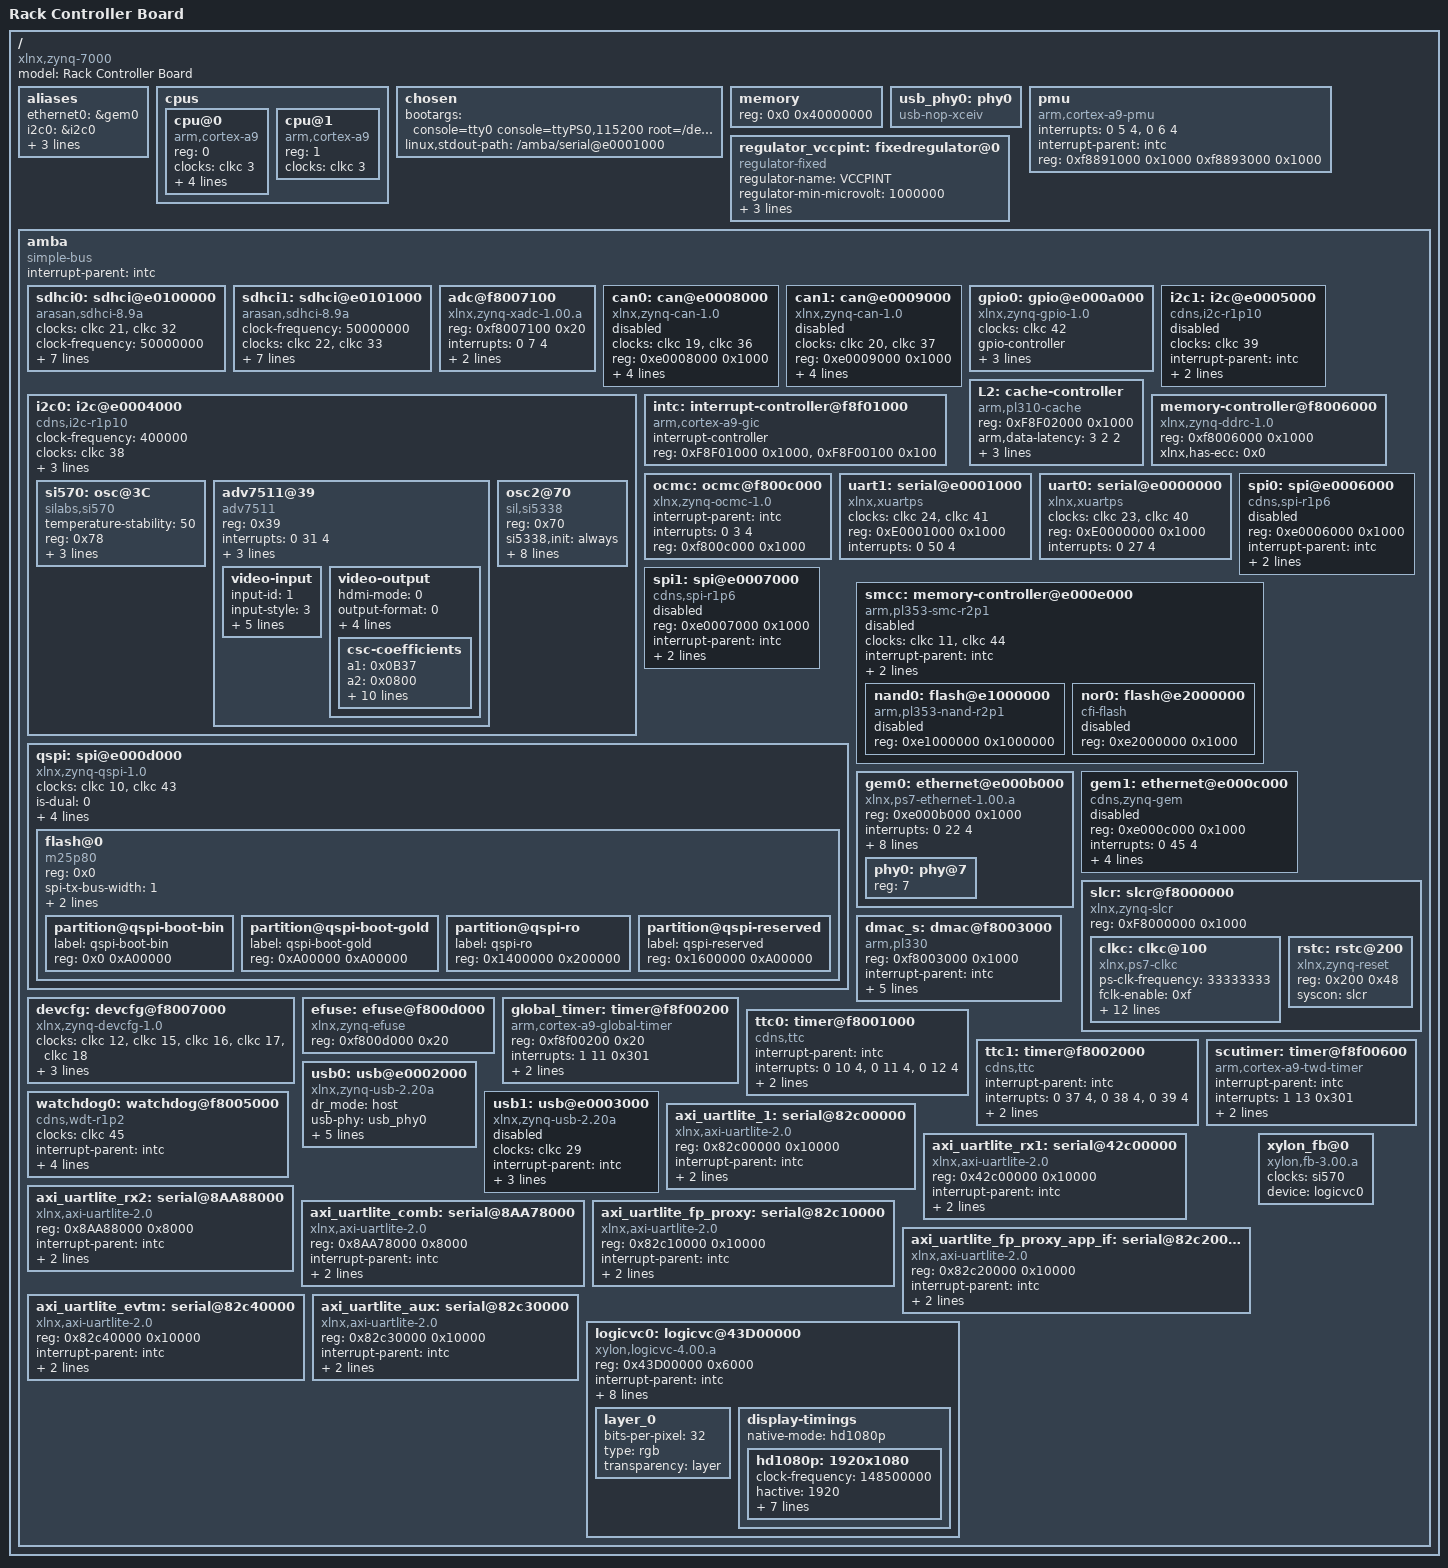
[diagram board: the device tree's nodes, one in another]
/ {
	model = "Rack Controller Board";
	compatible = "xlnx,zynq-7000";

	aliases {
		ethernet0 = &gem0;
		i2c0 = &i2c0;
		serial0 = &uart1;
		mmc0 = &sdhci0;
		mmc1 = &sdhci1;
	};

	cpus {
		#address-cells = <1>;
		#size-cells = <0>;

		cpu@0 {
			compatible = "arm,cortex-a9";
			device_type = "cpu";
			reg = <0>;
			clocks = <&clkc 3>;
			clock-latency = <1000>;
			cpu0-supply = <&regulator_vccpint>;
			operating-points = <
				/* kHz    uV */
				999999  1000000
				666667  1000000
				333334  1000000
			>;
		};

		cpu@1 {
			compatible = "arm,cortex-a9";
			device_type = "cpu";
			reg = <1>;
			clocks = <&clkc 3>;
		};
	};

	chosen {
		bootargs = "console=tty0 console=ttyPS0,115200 root=/dev/mmcblk0p2 rw earlyprintk ipv6.disable=1 consoleblank=0 rootwait";
		linux,stdout-path = "/amba/serial@e0001000";
	};

	memory {
		device_type = "memory";
		reg = <0x0 0x40000000>;
	};

	usb_phy0: phy0 {
		compatible = "usb-nop-xceiv";
		#phy-cells = <0>;
	};

	pmu {
		compatible = "arm,cortex-a9-pmu";
		interrupts = <0 5 4>, <0 6 4>;
		interrupt-parent = <&intc>;
		reg = < 0xf8891000 0x1000 0xf8893000 0x1000 >;
	};

	regulator_vccpint: fixedregulator@0 {
		compatible = "regulator-fixed";
		regulator-name = "VCCPINT";
		regulator-min-microvolt = <1000000>;
		regulator-max-microvolt = <1000000>;
		regulator-boot-on;
		regulator-always-on;
	};

	amba {
		compatible = "simple-bus";
		#address-cells = <1>;
		#size-cells = <1>;
		interrupt-parent = <&intc>;
		ranges;

		sdhci0: sdhci@e0100000 {
			compatible = "arasan,sdhci-8.9a";
			clock-names = "clk_xin", "clk_ahb";
			clocks = <&clkc 21>, <&clkc 32>;
			clock-frequency=<50000000>;
			status = "okay";
			xlnx,has-power = <0x0>;
			xlnx,has-wp = <0x1>;
			xlnx,has-cd = <0x1>;
			interrupt-parent = <&intc>;
			interrupts = <0 24 4>;
			reg = <0xe0100000 0x1000>;
			broken-adma2;
		};

		sdhci1: sdhci@e0101000 {
			compatible = "arasan,sdhci-8.9a";
			status = "okay";
			clock-frequency=<50000000>;
			clock-names = "clk_xin", "clk_ahb";
			clocks = <&clkc 22>, <&clkc 33>;
			xlnx,has-power = <0x0>;
			xlnx,has-wp = <0x1>;
			xlnx,has-cd = <0x1>;
			interrupt-parent = <&intc>;
			interrupts = <0 47 4>;
			reg = <0xe0101000 0x1000>;
			broken-adma2;
		};

		adc@f8007100 {
			compatible = "xlnx,zynq-xadc-1.00.a";
			reg = <0xf8007100 0x20>;
			interrupts = <0 7 4>;
			interrupt-parent = <&intc>;
			clocks = <&clkc 12>;
		};

		can0: can@e0008000 {
			compatible = "xlnx,zynq-can-1.0";
			status = "disabled";
			clocks = <&clkc 19>, <&clkc 36>;
			clock-names = "can_clk", "pclk";
			reg = <0xe0008000 0x1000>;
			interrupts = <0 28 4>;
			interrupt-parent = <&intc>;
			tx-fifo-depth = <0x40>;
			rx-fifo-depth = <0x40>;
		};

		can1: can@e0009000 {
			compatible = "xlnx,zynq-can-1.0";
			status = "disabled";
			clocks = <&clkc 20>, <&clkc 37>;
			clock-names = "can_clk", "pclk";
			reg = <0xe0009000 0x1000>;
			interrupts = <0 51 4>;
			interrupt-parent = <&intc>;
			tx-fifo-depth = <0x40>;
			rx-fifo-depth = <0x40>;
		};

		gpio0: gpio@e000a000 {
			compatible = "xlnx,zynq-gpio-1.0";
			#gpio-cells = <2>;
			clocks = <&clkc 42>;
			gpio-controller;
			interrupt-parent = <&intc>;
			interrupts = <0 20 4>;
			reg = <0xe000a000 0x1000>;
		};

		i2c0: i2c@e0004000 {
			compatible = "cdns,i2c-r1p10";
			status = "okay";
			clock-frequency = <400000>;
			clocks = <&clkc 38>;
			interrupt-parent = <&intc>;
			interrupts = <0 25 4>;
			reg = <0xe0004000 0x1000>;
			#address-cells = <1>;
			#size-cells = <0>;
			si570: osc@3C {
	       	       	       #clock-cells = <0>;
	       	       	       compatible = "silabs,si570";
	       	       	       temperature-stability = <50>;
	       	       	       //reg = <0x3C>;
	       	       	       reg = <0x78>;
	       	       	       factory-fout = <148500000>;
	       	       	       initial-fout = <148500000>;
	       	       	       clock-frequency = <148500000>;
		       	       };
			adv7511@39 {
				compatible = "adv7511";
	       	       		   reg = <0x39>;
		      		   interrupts = <0 31 4>;
               	       		   interrupt-parent = <&intc>;
	       	       		   dma-request = <&logicvc0>;
               	       		   edid-addr = <0x50>;
               	       		   video-input {
	       		   	    		 input-id = <1>;
                  	   			 input-style = <3>;
                           			 input-color-depth = <8>;
                           			 bit-justification = <1>;
                           			 hsync-polarity = <0>;
                           			 vsync-polarity = <0>;
                           			 clock-delay = <3>;
	      		   			 };
              	       		   video-output {
              		   	   		hdmi-mode = <0>;
                           			output-format = <0>;
                           			output-color-space = <0>;
                           			up-conversion = <0>;
                           			csc-enable = <1>;
                           			csc-scaling-factor = <2>;
                           			csc-coefficients {
			   	   			a1 = <0x0B37>;
			   	   			a2 = <0x0800>;
				   			a3 = <0x0000>;
				   			a4 = <0x1A86>;
				   			b1 = <0x1A49>;
				   			b2 = <0x0800>;
				   			b3 = <0x1D3F>;
				   			b4 = <0x0422>;
				   			c1 = <0x0000>;
				   			c2 = <0x0800>;
				   			c3 = <0x0E2D>;
				   			c4 = <0x1914>;
                           	   			};
              		   			};

				};
			osc2@70 {
				compatible = "sil,si5338";
				reg = <0x70>;
				//compatible = "si5338";
				//reg = <0x30>;
				si5338,init="always"; 
				si5338,in_frequency12xo= <25000000>; 
				si5338,pll_freq_int= <2400000000>;  
				si5338,out0_freq_int= <120000000>;  
				si5338,out1_freq_int= <120000000>;  
				si5338,out2_freq_int= <120000000>;  
				si5338,out3_freq_int= <120000000>;  
				si5338,2V5_LVDS=    <0 1 2 3>;
				si5338,output_en=   <0 2 3>; 
				};
		};

		i2c1: i2c@e0005000 {
			compatible = "cdns,i2c-r1p10";
			status = "disabled";
			clocks = <&clkc 39>;
			interrupt-parent = <&intc>;
			interrupts = <0 48 4>;
			reg = <0xe0005000 0x1000>;
			#address-cells = <1>;
			#size-cells = <0>;
		};

		intc: interrupt-controller@f8f01000 {
			compatible = "arm,cortex-a9-gic";
			#interrupt-cells = <3>;
			interrupt-controller;
			reg = <0xF8F01000 0x1000>,
			      <0xF8F00100 0x100>;
		};

		L2: cache-controller {
			compatible = "arm,pl310-cache";
			reg = <0xF8F02000 0x1000>;
			arm,data-latency = <3 2 2>;
			arm,tag-latency = <2 2 2>;
			cache-unified;
			cache-level = <2>;
		};

		memory-controller@f8006000 {
			compatible = "xlnx,zynq-ddrc-1.0";
			reg = <0xf8006000 0x1000>;
			xlnx,has-ecc = <0x0>;
		};

		ocmc: ocmc@f800c000 {
			compatible = "xlnx,zynq-ocmc-1.0";
			interrupt-parent = <&intc>;
			interrupts = <0 3 4>;
			reg = <0xf800c000 0x1000>;
		};

		uart1: serial@e0001000 {
			compatible = "xlnx,xuartps";
			status = "okay";
			clocks = <&clkc 24>, <&clkc 41>;
			clock-names = "uart_clk", "pclk";
			reg = <0xE0001000 0x1000>;
			interrupts = <0 50 4>;
		};

		uart0: serial@e0000000 {
			compatible = "xlnx,xuartps";
			status = "okay";
			clocks = <&clkc 23>, <&clkc 40>;
			clock-names = "uart_clk", "pclk";
			reg = <0xE0000000 0x1000>;
			interrupts = <0 27 4>;
		};

		spi0: spi@e0006000 {
			compatible = "cdns,spi-r1p6";
			reg = <0xe0006000 0x1000>;
			status = "disabled";
			interrupt-parent = <&intc>;
			interrupts = <0 26 4>;
			clock-names = "ref_clk", "pclk";
			clocks = <&clkc 25>, <&clkc 34>;
			#address-cells = <1>;
			#size-cells = <0>;
		};

		spi1: spi@e0007000 {
			compatible = "cdns,spi-r1p6";
			reg = <0xe0007000 0x1000>;
			status = "disabled";
			interrupt-parent = <&intc>;
			interrupts = <0 49 4>;
			clocks = <&clkc 26>, <&clkc 35>;
			clock-names = "ref_clk", "pclk";
			#address-cells = <1>;
			#size-cells = <0>;
		};

		qspi: spi@e000d000 {
			clock-names = "ref_clk", "pclk";
			clocks = <&clkc 10>, <&clkc 43>;
			compatible = "xlnx,zynq-qspi-1.0";
	        status = "okay";
	      	is-dual = <0>;
	      	num-cs = <1>;
	      	//xlnx,fb-clk = <0x1>;
			//xlnx,qspi-mode = <0x0>;
			interrupt-parent = <&intc>;
			interrupts = <0 19 4>;
			reg = <0xe000d000 0x1000>;
			#address-cells = <1>;
			#size-cells = <0>;
	      	flash@0 {
				//compatible = "n25q256a13";
                //compatible = "micron,n25q256", "jedec,spi-nor";
                compatible = "m25p80";
				reg = <0x0>;
				spi-tx-bus-width = <1>;
				spi-rx-bus-width = <1>;
				spi-max-frequency = <50000000>;
				#address-cells = <1>;
				#size-cells = <1>;
				partition@qspi-boot-bin {
				  label = "qspi-boot-bin";
				  reg = <0x0 0xA00000>;
				  };
				partition@qspi-boot-gold {
				  label = "qspi-boot-gold";
				  reg = <0xA00000 0xA00000>;
			 	};			
				partition@qspi-ro {
				  label = "qspi-ro";
				  reg = <0x1400000 0x200000>;
			 	};			
				partition@qspi-reserved {
				  label = "qspi-reserved";
				  reg = <0x1600000 0xA00000>;
			 	};			
			};
		};

		smcc: memory-controller@e000e000 {
			#address-cells = <1>;
			#size-cells = <1>;
			status = "disabled";
			clock-names = "memclk", "aclk";
			clocks = <&clkc 11>, <&clkc 44>;
			compatible = "arm,pl353-smc-r2p1";
			interrupt-parent = <&intc>;
			interrupts = <0 18 4>;
			ranges ;
			reg = <0xe000e000 0x1000>;
			nand0: flash@e1000000 {
				status = "disabled";
				compatible = "arm,pl353-nand-r2p1";
				reg = <0xe1000000 0x1000000>;
				#address-cells = <0x1>;
				#size-cells = <0x1>;
			};
			nor0: flash@e2000000 {
				status = "disabled";
				compatible = "cfi-flash";
				reg = <0xe2000000 0x1000>;
				#address-cells = <1>;
				#size-cells = <1>;
			};
		};

		gem0: ethernet@e000b000 {
			compatible = "xlnx,ps7-ethernet-1.00.a";
			reg = <0xe000b000 0x1000>;
			status = "okay";
			interrupts = <0 22 4>;
			clocks = <&clkc 13>, <&clkc 30>;
			clock-names = "ref_clk", "aper_clk";
			local-mac-address = [00 0a 35 00 00 00];
			xlnx,has-mdio = <0x1>;
			phy-mode = "rgmii-id";
			#address-cells = <1>;
			#size-cells = <0>;
			phy-handle = <&phy0>;
	      		enet-reset = "MIO 47";
	      		eth-mode = <0x1>;
	      		ptp-enet-clock = <111111115>;
	      		phy0: phy@7 {
	      	    	      //compatible = "marvell,88e1116r";
	      	    	      //device_type = "ethernet-phy";
	      	    	      reg = <7>;
		    	} ;
		};

		gem1: ethernet@e000c000 {
			compatible = "cdns,zynq-gem", "cdns,gem";
			reg = <0xe000c000 0x1000>;
			status = "disabled";
			interrupts = <0 45 4>;
			interrupt-parent = <&intc>;
			clocks = <&clkc 14>, <&clkc 31>;
			clock-names = "ref_clk", "aper_clk";
			local-mac-address = [00 0a 35 00 00 00];
			xlnx,has-mdio = <0x1>;
			#address-cells = <1>;
			#size-cells = <0>;
		};

		slcr: slcr@f8000000 {
			#address-cells = <1>;
			#size-cells = <1>;
			compatible = "xlnx,zynq-slcr", "syscon", "simple-mfd";
			reg = <0xF8000000 0x1000>;
			ranges;
			clkc: clkc@100 {
				#clock-cells = <1>;
				compatible = "xlnx,ps7-clkc";
				ps-clk-frequency = <33333333>;
				fclk-enable = <0xf>;
				clock-output-names = "armpll", "ddrpll", "iopll", "cpu_6or4x",
						"cpu_3or2x", "cpu_2x", "cpu_1x", "ddr2x", "ddr3x",
						"dci", "lqspi", "smc", "pcap", "gem0", "gem1",
						"fclk0", "fclk1", "fclk2", "fclk3", "can0", "can1",
						"sdio0", "sdio1", "uart0", "uart1", "spi0", "spi1",
						"dma", "usb0_aper", "usb1_aper", "gem0_aper",
						"gem1_aper", "sdio0_aper", "sdio1_aper",
						"spi0_aper", "spi1_aper", "can0_aper", "can1_aper",
						"i2c0_aper", "i2c1_aper", "uart0_aper", "uart1_aper",
						"gpio_aper", "lqspi_aper", "smc_aper", "swdt",
						"dbg_trc", "dbg_apb";
				reg = <0x100 0x100>;
			};

			rstc: rstc@200 {
				compatible = "xlnx,zynq-reset";
				reg = <0x200 0x48>;
				#reset-cells = <1>;
				syscon = <&slcr>;
			};
		};

		dmac_s: dmac@f8003000 {
			compatible = "arm,pl330", "arm,primecell";
			reg = <0xf8003000 0x1000>;
			interrupt-parent = <&intc>;
			interrupt-names = "abort", "dma0", "dma1", "dma2", "dma3",
				"dma4", "dma5", "dma6", "dma7";
			interrupts = <0 13 4>,
			             <0 14 4>, <0 15 4>,
			             <0 16 4>, <0 17 4>,
			             <0 40 4>, <0 41 4>,
			             <0 42 4>, <0 43 4>;
			#dma-cells = <1>;
			#dma-channels = <8>;
			#dma-requests = <4>;
			clocks = <&clkc 27>;
			clock-names = "apb_pclk";
		};

		devcfg: devcfg@f8007000 {
			clock-names = "ref_clk", "fclk0", "fclk1", "fclk2", "fclk3";
			clocks = <&clkc 12>, <&clkc 15>, <&clkc 16>, <&clkc 17>, <&clkc 18>;
			compatible = "xlnx,zynq-devcfg-1.0";
			interrupt-parent = <&intc>;
			interrupts = <0 8 4>;
			reg = <0xf8007000 0x100>;
		};

                efuse: efuse@f800d000 {
                        compatible = "xlnx,zynq-efuse";
                        reg = <0xf800d000 0x20>;
                };

		global_timer: timer@f8f00200 {
			compatible = "arm,cortex-a9-global-timer";
			reg = <0xf8f00200 0x20>;
			interrupts = <1 11 0x301>;
			interrupt-parent = <&intc>;
			clocks = <&clkc 4>;
		};

		ttc0: timer@f8001000 {
			interrupt-parent = <&intc>;
			interrupts = <0 10 4>, <0 11 4>, <0 12 4>;
			compatible = "cdns,ttc";
			clocks = <&clkc 6>;
			reg = <0xF8001000 0x1000>;
		};

		ttc1: timer@f8002000 {
			interrupt-parent = <&intc>;
			interrupts = <0 37 4>, <0 38 4>, <0 39 4>;
			compatible = "cdns,ttc";
			clocks = <&clkc 6>;
			reg = <0xF8002000 0x1000>;
		};

		scutimer: timer@f8f00600 {
			interrupt-parent = <&intc>;
			interrupts = <1 13 0x301>;
			compatible = "arm,cortex-a9-twd-timer";
			reg = <0xf8f00600 0x20>;
			clocks = <&clkc 4>;
		};

		watchdog0: watchdog@f8005000 {
			clocks = <&clkc 45>;
			compatible = "cdns,wdt-r1p2";
			status = "okay";
			interrupt-parent = <&intc>;
			interrupts = <0 9 1>;
			reg = <0xf8005000 0x1000>;
			reset-on-timeout;
			timeout-sec = <10>;
		};

		usb0: usb@e0002000 {
			compatible = "xlnx,zynq-usb-2.20a", "chipidea,usb2";
	     		status = "okay";
	    		dr_mode = "host";
	     		usb-phy = <&usb_phy0>;
			clocks = <&clkc 28>;
			interrupt-parent = <&intc>;
			interrupts = <0 21 4>;
			reg = <0xe0002000 0x1000>;
			phy_type = "ulpi";
		};

		usb1: usb@e0003000 {
			compatible = "xlnx,zynq-usb-2.20a", "chipidea,usb2";
			status = "disabled";
			clocks = <&clkc 29>;
			interrupt-parent = <&intc>;
			interrupts = <0 44 4>;
			reg = <0xe0003000 0x1000>;
			phy_type = "ulpi";
		};

		// test uart
		axi_uartlite_1: serial@82c00000 {
				compatible = "xlnx,axi-uartlite-2.0", "xlnx,xps-uartlite-1.00.a";
				reg = <0x82c00000 0x10000>;
				interrupt-parent = <&intc>;
				interrupts = <0 29 1>;
				clock = <100000000>;
		} ;
		// rx1 uart
		axi_uartlite_rx1: serial@42c00000 {
				compatible = "xlnx,axi-uartlite-2.0", "xlnx,xps-uartlite-1.00.a";
				reg = <0x42c00000 0x10000>;
				interrupt-parent = <&intc>;
				interrupts = <0 57 1>;
				clock = <100000000>;
		} ;
		// rx2 uart
		axi_uartlite_rx2: serial@8AA88000 {
				compatible = "xlnx,axi-uartlite-2.0", "xlnx,xps-uartlite-1.00.a";
				reg = <0x8AA88000 0x8000>;
				interrupt-parent = <&intc>;
				interrupts = <0 58 1>;
				clock = <100000000>;
		} ;
		// comb uart
		axi_uartlite_comb: serial@8AA78000 {
				compatible = "xlnx,axi-uartlite-2.0", "xlnx,xps-uartlite-1.00.a";
				reg = <0x8AA78000 0x8000>;
				interrupt-parent = <&intc>;
				interrupts = <0 59 1>;
				clock = <100000000>;
		} ;

		// front panel proxy
		axi_uartlite_fp_proxy: serial@82c10000 {
				compatible = "xlnx,axi-uartlite-2.0", "xlnx,xps-uartlite-1.00.a";
				reg = <0x82c10000 0x10000>;
				interrupt-parent = <&intc>;
				interrupts = <0 52 1>;
				clock = <100000000>;
		} ;

		// front panel proxy app if uart
		axi_uartlite_fp_proxy_app_if: serial@82c20000 {
				compatible = "xlnx,axi-uartlite-2.0", "xlnx,xps-uartlite-1.00.a";
				reg = <0x82c20000 0x10000>;
				interrupt-parent = <&intc>;
				interrupts = <0 32 1>;
				clock = <100000000>;
		} ;

		// rev C EVTM uart
		axi_uartlite_evtm: serial@82c40000 {
				compatible = "xlnx,axi-uartlite-2.0", "xlnx,xps-uartlite-1.00.a";
				reg = <0x82c40000 0x10000>;
				interrupt-parent = <&intc>;
				interrupts = <0 34 1>;
				clock = <100000000>;
		} ;

		// rev C AUX uart
		axi_uartlite_aux: serial@82c30000 {
				compatible = "xlnx,axi-uartlite-2.0", "xlnx,xps-uartlite-1.00.a";
				reg = <0x82c30000 0x10000>;
				interrupt-parent = <&intc>;
				interrupts = <0 35 1>;
				clock = <100000000>;
		} ;

		logicvc0: logicvc@43D00000 {
			compatible = "xylon,logicvc-4.00.a";
			reg = <0x43D00000 0x6000>;
			interrupt-parent = <&intc>;
			interrupts = < 0 30 4 >;

			background-layer-bits-per-pixel = <32>;
			background-layer-type = "rgb";
			hsync-active-low;
			vsync-active-low;
			readable-regs;
			size-position;
			pixel-stride = <2048>;
			layer_0 {
				//address = <0x3C000000>;
	  			//buffer-offset = <1080>;
				bits-per-pixel = <32>;
				type = "rgb";
				transparency = "layer";
			};

			display-timings {
				native-mode = <&hd1080p>;
				hd1080p: 1920x1080 {
					 clock-frequency = <148500000>;
					 hactive = <1920>;
					 vactive = <1080>;
					 hfront-porch = <88>;
					 hback-porch = <148>;
					 hsync-len = <44>;
					 vfront-porch = <4>;
					 vback-porch = <36>;
					 vsync-len = <5>;
				};
			};

		} ;

		xylon_fb@0 {
			 compatible = "xylon,fb-3.00.a";
			 clocks = <&si570>;
			 device = <&logicvc0>;
			 //edid-video-mode;
			 //edid-print;
			 //vsync-irq;
			 //video-mode = "1920x1080";
		} ;

	} ;
};

